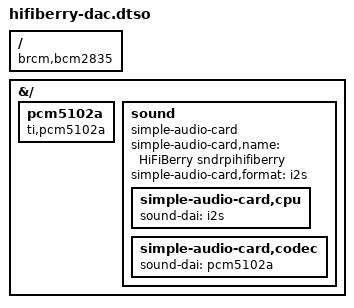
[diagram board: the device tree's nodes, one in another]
/dts-v1/;
/plugin/;

/ {
	compatible = "brcm,bcm2835";
};

&{/} {
	pcm5102a: pcm5102a {
		#sound-dai-cells = <0>;
		compatible = "ti,pcm5102a";
	};

	sound {
		compatible = "simple-audio-card";
		simple-audio-card,name = "HiFiBerry sndrpihifiberry";
		simple-audio-card,format = "i2s";

		simple-audio-card,cpu {
			sound-dai = <&i2s>;
		};

		simple-audio-card,codec {
			sound-dai = <&pcm5102a>;
		};
	};
};
